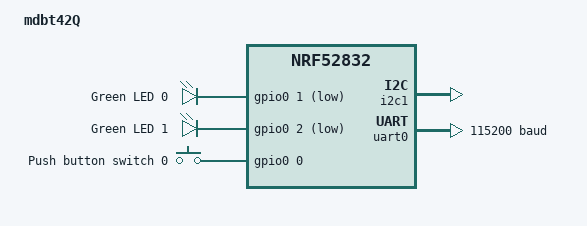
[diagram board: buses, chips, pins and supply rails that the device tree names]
// Copyright (c) 2023 Nordic Semiconductor ASA
// SPDX-License-Identifier: Apache-2.0

/dts-v1/;
#include <nordic/nrf52832_qfaa.dtsi>
#include "mdbt42q_nrf52-pinctrl.dtsi"
#include <zephyr/dt-bindings/input/input-event-codes.h>

/ {
	model = "mdbt42Q";
	compatible = "raytec,mdbt42q-nrf52";

	chosen {
		zephyr,console = &uart0;
		zephyr,shell-uart = &uart0;
		zephyr,uart-mcumgr = &uart0;
		zephyr,bt-mon-uart = &uart0;
		zephyr,bt-c2h-uart = &uart0;
		zephyr,sram = &sram0;
		zephyr,flash = &flash0;
		zephyr,code-partition = &slot0_partition;
	};
	
	leds {
		compatible = "gpio-leds";
		led0: led_0 {
			gpios = <&gpio0 1 GPIO_ACTIVE_LOW>;
			label = "Green LED 0";
		};
		led1: led_1 {
			gpios = <&gpio0 2 GPIO_ACTIVE_LOW>;
			label = "Green LED 1";
		};
	};
	
	buttons {
		compatible = "gpio-keys";
		button0: button_0 {
			gpios = <&gpio0 0 (GPIO_PULL_DOWN | GPIO_ACTIVE_HIGH)>;
			label = "Push button switch 0";
			zephyr,code = <INPUT_KEY_0>;
		};

	};

	
		/* These aliases are provided for compatibility with samples */
	aliases {
		led0 = &led0;
		led1 = &led1;
		sw0 = &button0;

	};
	


};

arduino_i2c: &i2c1 {
	compatible = "nordic,nrf-twi";
	status = "okay";
	pinctrl-0 = <&i2c1_default>;
	pinctrl-1 = <&i2c1_sleep>;
	pinctrl-names = "default", "sleep";
};

&uicr {
	gpio-as-nreset;
};

&gpio0 {
	status = "okay";
};

&uart0 {
	status = "okay";
	compatible = "nordic,nrf-uarte";
	current-speed = <115200>;
	pinctrl-0 = <&uart0_default>;
	pinctrl-1 = <&uart0_sleep>;
	pinctrl-names = "default", "sleep";
};

&flash0 {

	partitions {
		compatible = "fixed-partitions";
		#address-cells = <1>;
		#size-cells = <1>;

		boot_partition: partition@0 {
			label = "mcuboot";
			reg = <0x0 0xc000>;
		};
		slot0_partition: partition@c000 {
			label = "image-0";
			reg = <0xc000 0x32000>;
		};
		slot1_partition: partition@3e000 {
			label = "image-1";
			reg = <0x3e000 0x32000>;
		};
		scratch_partition: partition@70000 {
			label = "image-scratch";
			reg = <0x70000 0xa000>;
		};
		storage_partition: partition@7a000 {
			label = "storage";
			reg = <0x7a000 0x6000>;
		};
	};
};

